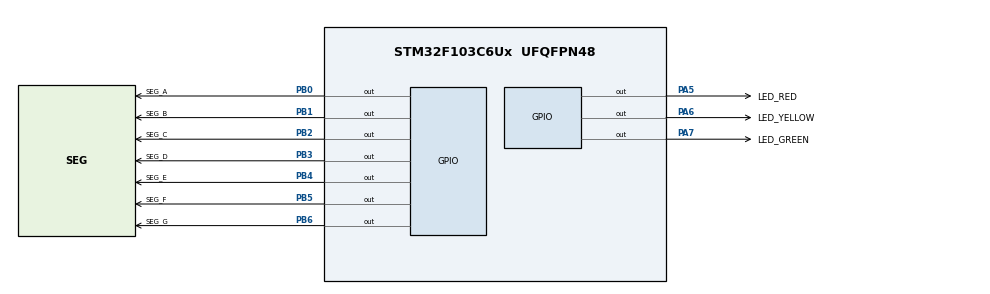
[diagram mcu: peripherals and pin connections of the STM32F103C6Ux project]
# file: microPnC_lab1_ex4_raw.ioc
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Mcu.Family=STM32F1
Mcu.Name=STM32F103C6Ux
Mcu.Package=UFQFPN48
NVIC.PriorityGroup=NVIC_PRIORITYGROUP_4
NVIC.TIM2_IRQn=true\:0\:0\:false\:false\:true\:true\:true\:true
PA5.GPIO_Label=LED_RED
PA5.Signal=GPIO_Output
PA6.GPIO_Label=LED_YELLOW
PA6.Signal=GPIO_Output
PA7.GPIO_Label=LED_GREEN
PA7.Signal=GPIO_Output
PB0.GPIO_Label=SEG_A
PB0.Signal=GPIO_Output
PB1.GPIO_Label=SEG_B
PB1.Signal=GPIO_Output
PB2.GPIO_Label=SEG_C
PB2.Signal=GPIO_Output
PB3.GPIO_Label=SEG_D
PB3.Signal=GPIO_Output
PB4.GPIO_Label=SEG_E
PB4.Signal=GPIO_Output
PB5.GPIO_Label=SEG_F
PB5.Signal=GPIO_Output
PB6.GPIO_Label=SEG_G
PB6.Signal=GPIO_Output
ProjectManager.HeapSize=0x200
ProjectManager.StackSize=0x400
ProjectManager.TargetToolchain=STM32CubeIDE
RCC.APB1Freq_Value=8000000
RCC.APB2Freq_Value=8000000
TIM2.Period=9
TIM2.Prescaler=7999
VP_SYS_VS_ND.Mode=No_Debug
VP_TIM2_VS_ClockSourceINT.Mode=Internal
board=custom

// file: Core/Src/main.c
/* USER CODE BEGIN Header */
/**
  ******************************************************************************
  * @file           : main.c
  * @brief          : Main program body
  ******************************************************************************
  * @attention
  *
  * Copyright (c) 2022 STMicroelectronics.
  * All rights reserved.
  *
  * This software is licensed under terms that can be found in the LICENSE file
  * in the root directory of this software component.
  * If no LICENSE file comes with this software, it is provided AS-IS.
  *
  ******************************************************************************
  */
#include "software_timer.h"
#include "led_modify.h"
#include "7_segment.h"
/* USER CODE END Header */
#include "main.h"
#include "tim.h"
#include "gpio.h"

void SystemClock_Config(void);

int main(void)
{

  /* MCU Configuration--------------------------------------------------------*/

  /* Reset of all peripherals, Initializes the Flash interface and the Systick. */
  HAL_Init();

  /* Configure the system clock */
  SystemClock_Config();

  /* Initialize all configured peripherals */
  MX_GPIO_Init();
  MX_TIM2_Init();
  /* USER CODE BEGIN 2 */
  HAL_TIM_Base_Start_IT(&htim2);
  LED_Setup(2, 2, 2);
  Seg_Setup(9);
  /* USER CODE END 2 */

  /* Infinite loop */
  /* USER CODE BEGIN WHILE */
  Set_Timer();
  while (1)
  {
	  if(timerFlag == 1){
		  Set_Timer();
		  LED_Alternating();
		  Display_7Seg();
	  }
    /* USER CODE END WHILE */

  }
}

void SystemClock_Config(void)
{
  RCC_OscInitTypeDef RCC_OscInitStruct = {0};
  RCC_ClkInitTypeDef RCC_ClkInitStruct = {0};

  /** Initializes the RCC Oscillators according to the specified parameters
  * in the RCC_OscInitTypeDef structure.
  */
  RCC_OscInitStruct.OscillatorType = RCC_OSCILLATORTYPE_HSI;
  RCC_OscInitStruct.HSIState = RCC_HSI_ON;
  RCC_OscInitStruct.HSICalibrationValue = RCC_HSICALIBRATION_DEFAULT;
  RCC_OscInitStruct.PLL.PLLState = RCC_PLL_NONE;
  if (HAL_RCC_OscConfig(&RCC_OscInitStruct) != HAL_OK)
  {
    Error_Handler();
  }

  /** Initializes the CPU, AHB and APB buses clocks
  */
  RCC_ClkInitStruct.ClockType = RCC_CLOCKTYPE_HCLK|RCC_CLOCKTYPE_SYSCLK
                              |RCC_CLOCKTYPE_PCLK1|RCC_CLOCKTYPE_PCLK2;
  RCC_ClkInitStruct.SYSCLKSource = RCC_SYSCLKSOURCE_HSI;
  RCC_ClkInitStruct.AHBCLKDivider = RCC_SYSCLK_DIV1;
  RCC_ClkInitStruct.APB1CLKDivider = RCC_HCLK_DIV1;
  RCC_ClkInitStruct.APB2CLKDivider = RCC_HCLK_DIV1;

  if (HAL_RCC_ClockConfig(&RCC_ClkInitStruct, FLASH_LATENCY_0) != HAL_OK)
  {
    Error_Handler();
  }
}

/* USER CODE BEGIN 4 */

void HAL_TIM_PeriodElapsedCallback(TIM_HandleTypeDef *htim){
	Timer_Run();
}
/* USER CODE END 4 */

void Error_Handler(void)
{
  __disable_irq();
  while (1)
  {
  }
}
